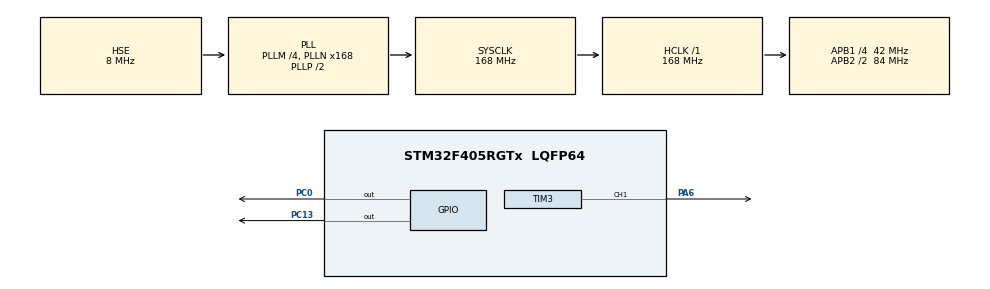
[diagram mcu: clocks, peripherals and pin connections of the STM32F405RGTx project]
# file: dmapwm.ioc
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Dma.Request0=TIM3_CH1/TRIG
Dma.TIM3_CH1/TRIG.0.Direction=DMA_MEMORY_TO_PERIPH
Dma.TIM3_CH1/TRIG.0.FIFOMode=DMA_FIFOMODE_DISABLE
Dma.TIM3_CH1/TRIG.0.Instance=DMA1_Stream4
Dma.TIM3_CH1/TRIG.0.MemDataAlignment=DMA_MDATAALIGN_HALFWORD
Dma.TIM3_CH1/TRIG.0.MemInc=DMA_MINC_ENABLE
Dma.TIM3_CH1/TRIG.0.Mode=DMA_CIRCULAR
Dma.TIM3_CH1/TRIG.0.PeriphDataAlignment=DMA_PDATAALIGN_HALFWORD
Dma.TIM3_CH1/TRIG.0.PeriphInc=DMA_PINC_DISABLE
Dma.TIM3_CH1/TRIG.0.Priority=DMA_PRIORITY_MEDIUM
Mcu.Family=STM32F4
Mcu.Name=STM32F405RGTx
Mcu.Package=LQFP64
Mcu.UserConstants=LED_PERIOD,104;LED_PRE,0
NVIC.DMA1_Stream4_IRQn=true\:0\:0\:false\:false\:true\:false\:true
NVIC.PriorityGroup=NVIC_PRIORITYGROUP_4
NVIC.TIM4_IRQn=true\:1\:0\:true\:false\:true\:true\:true
PA13.Mode=Trace_Asynchronous_SW
PA13.Signal=SYS_JTMS-SWDIO
PA14.Mode=Trace_Asynchronous_SW
PA14.Signal=SYS_JTCK-SWCLK
PA6.GPIO_PuPd=GPIO_NOPULL
PA6.GPIO_Speed=GPIO_SPEED_FREQ_VERY_HIGH
PA6.Signal=S_TIM3_CH1
PB3.Mode=Trace_Asynchronous_SW
PB3.Signal=SYS_JTDO-SWO
PC0.Signal=GPIO_Output
PC13-ANTI_TAMP.Signal=GPIO_Output
PH0-OSC_IN.Mode=HSE-External-Oscillator
PH0-OSC_IN.Signal=RCC_OSC_IN
PH1-OSC_OUT.Mode=HSE-External-Oscillator
PH1-OSC_OUT.Signal=RCC_OSC_OUT
ProjectManager.HeapSize=0x200
ProjectManager.StackSize=0x400
ProjectManager.TargetToolchain=STM32CubeIDE
RCC.48MHZClocksFreq_Value=48000000
RCC.AHBFreq_Value=168000000
RCC.APB1CLKDivider=RCC_HCLK_DIV4
RCC.APB1Freq_Value=42000000
RCC.APB1TimFreq_Value=84000000
RCC.APB2CLKDivider=RCC_HCLK_DIV2
RCC.APB2Freq_Value=84000000
RCC.APB2TimFreq_Value=168000000
RCC.CortexFreq_Value=168000000
RCC.HCLKFreq_Value=168000000
RCC.HSE_VALUE=8000000
RCC.HSI_VALUE=16000000
RCC.LSE_VALUE=32768
RCC.PLLM=4
RCC.PLLN=168
RCC.PLLQ=7
RCC.PLLSourceVirtual=RCC_PLLSOURCE_HSE
RCC.SYSCLKFreq_VALUE=168000000
RCC.SYSCLKSource=RCC_SYSCLKSOURCE_PLLCLK
RCC.VCOOutputFreq_Value=336000000
SH.S_TIM3_CH1.0=TIM3_CH1,PWM Generation1 CH1
TIM3.AutoReloadPreload=TIM_AUTORELOAD_PRELOAD_ENABLE
TIM3.Channel-PWM\ Generation1\ CH1=TIM_CHANNEL_1
TIM3.OCFastMode_PWM-PWM\ Generation1\ CH1=TIM_OCFAST_ENABLE
TIM3.Period=LED_PERIOD
TIM3.Prescaler=LED_PRE
TIM3.Pulse-PWM\ Generation1\ CH1=0
TIM3.TIM_MasterOutputTrigger=TIM_TRGO_UPDATE
TIM4.Period=4999
TIM4.Prescaler=8399
VP_TIM3_VS_ClockSourceINT.Mode=Internal
VP_TIM4_VS_ClockSourceINT.Mode=Internal
board=custom

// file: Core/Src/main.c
/* USER CODE BEGIN Header */
/**
 ******************************************************************************
 * @file           : main.c
 * @brief          : Main program body
 ******************************************************************************
 * @attention
 *
 * <h2><center>&copy; Copyright (c) 2020 Lars Thomsen &lt;lbthomsen@gmail.com&gt;
 * All rights reserved.</center></h2>
 *
 * This software component is licensed by lbthomsen under DWYDWP (Do What You
 * Damn Well Please) license.
 *
 ******************************************************************************
 */
/* USER CODE END Header */
#include "main.h"

/* USER CODE BEGIN Includes */
#include <stdio.h>
/* USER CODE END Includes */

/* USER CODE BEGIN PD */

// Buffer allocated will be twice this
#define BUFFER_SIZE 24

// LED on/off counts.  PWM timer is running 104 counts.
#define LED_PERIOD 104
#define LED_OFF 33
#define LED_ON 71
#define LED_RESET_CYCLES 10 // Found experimentally and way longer than specified in datasheet

// Define LED driver state machine states
#define LED_RES 0 // Reset state - all values should be 0 for 2 buffers
#define LED_DAT 1 // Data state - values should be taken from led_values

#define LED_ROWS 8 // The dma buffer update handles the rows and cols sequentially
#define LED_COLS 8
#define G 0
#define R 1
#define B 2

/* USER CODE END PD */

TIM_HandleTypeDef htim3;
TIM_HandleTypeDef htim4;
DMA_HandleTypeDef hdma_tim3_ch1_trig;

/* USER CODE BEGIN PV */

uint16_t dma_buffer[BUFFER_SIZE * 2] = { 0 };

uint16_t *dma_buffer_pointer;

uint8_t led_value[LED_ROWS][LED_COLS][3] = { 0 };

uint8_t led_state = LED_RES;
uint8_t res_cnt = 0;
uint8_t led_col = 0;
uint8_t led_row = 0;

uint32_t update_count = 0;

/* USER CODE END PV */

void SystemClock_Config(void);
static void MX_GPIO_Init(void);
static void MX_DMA_Init(void);
static void MX_TIM3_Init(void);
static void MX_TIM4_Init(void);

/* USER CODE BEGIN 0 */

int _write(int file, char *ptr, int len) {
	for (int i = 0; i < len; i++)
		ITM_SendChar((*ptr++));
	return len;
}

/*
 * Update next 24 bits in the dma buffer - assume dma_buffer_pointer is pointing
 * to the buffer that is safe to update.
 *
 * At the moment this one is in dire need of optimization!
 *
 */
static inline void update_buffer_next() {

	// For debugging and measuring calculation time - toggle GPIO pin
	HAL_GPIO_WritePin(GPIOC, GPIO_PIN_0, GPIO_PIN_SET);

	// A simple state machine - we're either resetting (two buffers worth of zeros) or
	// we are transmitting data

	if (led_state == LED_RES) { // Reset state - 10 or more full buffers of zeros

		for (uint8_t i = 0; i < BUFFER_SIZE; i++) { // Fill buffer with zeros
			*(uint16_t*) dma_buffer_pointer = (uint16_t) 0;
			dma_buffer_pointer++;
		}

		res_cnt++;

		if (res_cnt >= LED_RESET_CYCLES) { // done enough reset cycles
			led_col = 0;	// prepare to send data
			led_row = 0;
			led_state = LED_DAT;
		}

	} else { // LED state

		// First let's deal with the current LED
		uint8_t *led = led_value[led_col][led_row];
		for (uint8_t c = 0; c < 3; c++) { // This is the bitch - need to be optimized!
			uint8_t value = led[c];
			// Now deal with each bit
			for (uint8_t b = 0; b < 8; b++) {
				*(uint16_t*) dma_buffer_pointer =
						value >> (7 - b) != 0 ? LED_ON : LED_OFF;
				dma_buffer_pointer++;
			}
		}

		// Now move to next LED switching to reset state when all leds have been updated
		led_col++; // Next column
		if (led_col >= LED_COLS) { // reached top
			led_col = 0; // back to first
			led_row++; // and move on to next row
			if (led_row >= LED_ROWS) { // reached end
				update_count++;
				res_cnt = 0;
				led_state = LED_RES;
			}
		}

	}

	HAL_GPIO_WritePin(GPIOC, GPIO_PIN_0, GPIO_PIN_RESET);

}

// Handle built-in blue led hanging off of C13
void HAL_TIM_PeriodElapsedCallback(TIM_HandleTypeDef *htim) {
	if (htim->Instance == TIM4) {
		HAL_GPIO_TogglePin(GPIOC, GPIO_PIN_13);
	}
}

// Done sending first half of the DMA buffer - this can now safely be updated
void HAL_TIM_PWM_PulseFinishedHalfCpltCallback(TIM_HandleTypeDef *htim) {

	if (htim->Instance == TIM3) {
		dma_buffer_pointer = &dma_buffer[0];
		update_buffer_next();
	}

}

// Done sending the second half of the DMA buffer - this can now be safely updated
void HAL_TIM_PWM_PulseFinishedCallback(TIM_HandleTypeDef *htim) {

	if (htim->Instance == TIM3) {
		dma_buffer_pointer = &dma_buffer[BUFFER_SIZE];
		update_buffer_next();
	}

}

// Just throw values into led_value array - the dma interrupt will
// handle updating the dma buffer when needed
void setLedValue(uint8_t col, uint8_t row, uint8_t r, uint8_t g, uint8_t b) {

	led_value[col][row][R] = r;
	led_value[col][row][G] = g;
	led_value[col][row][B] = b;

}

/* USER CODE END 0 */

int main(void)
{

  /* MCU Configuration--------------------------------------------------------*/

  /* Reset of all peripherals, Initializes the Flash interface and the Systick. */
  HAL_Init();

  /* Configure the system clock */
  SystemClock_Config();

  /* Initialize all configured peripherals */
  MX_GPIO_Init();
  MX_DMA_Init();
  MX_TIM3_Init();
  MX_TIM4_Init();
  /* USER CODE BEGIN 2 */

	// Start the timer to get the blue led flashing every second
	HAL_TIM_Base_Start_IT(&htim4);

	// Start DMA to feed the PWM with values
	HAL_TIM_PWM_Start_DMA(&htim3, TIM_CHANNEL_1, (uint32_t*) dma_buffer,
	BUFFER_SIZE * 2);

	printf("Firing up!\n");

  /* USER CODE END 2 */

  /* Infinite loop */
  /* USER CODE BEGIN WHILE */

	uint8_t led_value_counter = 0;

	uint32_t then = 0;

	while (1) {

		uint32_t now = HAL_GetTick();
		if (now % 1000 == 0 && now != then) {

			printf("tick %5lu (update count: %5lu)\n", now, update_count);

			switch (led_value_counter) {
			case 0:
				setLedValue(0, 0, 10, 0, 0);
				break;
			case 1:
				setLedValue(0, 0, 0, 10, 0);
				break;
			case 2:
				setLedValue(0, 0, 0, 0, 10);
				break;
			case 3:
				setLedValue(0, 0, 10, 10, 0);
				break;
			case 4:
				setLedValue(0, 0, 10, 0, 10);
				break;
			case 5:
				setLedValue(0, 0, 0, 10, 10);
				break;
			case 6:
				setLedValue(0, 0, 10, 10, 10);
				break;
			}

			led_value_counter++;
			if (led_value_counter >= 7)
				led_value_counter = 0;

			then = now;
		}

    /* USER CODE END WHILE */

	}
}

void SystemClock_Config(void)
{
  RCC_OscInitTypeDef RCC_OscInitStruct = {0};
  RCC_ClkInitTypeDef RCC_ClkInitStruct = {0};

  /** Configure the main internal regulator output voltage
  */
  __HAL_RCC_PWR_CLK_ENABLE();
  __HAL_PWR_VOLTAGESCALING_CONFIG(PWR_REGULATOR_VOLTAGE_SCALE1);
  /** Initializes the RCC Oscillators according to the specified parameters
  * in the RCC_OscInitTypeDef structure.
  */
  RCC_OscInitStruct.OscillatorType = RCC_OSCILLATORTYPE_HSE;
  RCC_OscInitStruct.HSEState = RCC_HSE_ON;
  RCC_OscInitStruct.PLL.PLLState = RCC_PLL_ON;
  RCC_OscInitStruct.PLL.PLLSource = RCC_PLLSOURCE_HSE;
  RCC_OscInitStruct.PLL.PLLM = 4;
  RCC_OscInitStruct.PLL.PLLN = 168;
  RCC_OscInitStruct.PLL.PLLP = RCC_PLLP_DIV2;
  RCC_OscInitStruct.PLL.PLLQ = 7;
  if (HAL_RCC_OscConfig(&RCC_OscInitStruct) != HAL_OK)
  {
    Error_Handler();
  }
  /** Initializes the CPU, AHB and APB buses clocks
  */
  RCC_ClkInitStruct.ClockType = RCC_CLOCKTYPE_HCLK|RCC_CLOCKTYPE_SYSCLK
                              |RCC_CLOCKTYPE_PCLK1|RCC_CLOCKTYPE_PCLK2;
  RCC_ClkInitStruct.SYSCLKSource = RCC_SYSCLKSOURCE_PLLCLK;
  RCC_ClkInitStruct.AHBCLKDivider = RCC_SYSCLK_DIV1;
  RCC_ClkInitStruct.APB1CLKDivider = RCC_HCLK_DIV4;
  RCC_ClkInitStruct.APB2CLKDivider = RCC_HCLK_DIV2;

  if (HAL_RCC_ClockConfig(&RCC_ClkInitStruct, FLASH_LATENCY_5) != HAL_OK)
  {
    Error_Handler();
  }
}

static void MX_TIM3_Init(void)
{

  TIM_ClockConfigTypeDef sClockSourceConfig = {0};
  TIM_MasterConfigTypeDef sMasterConfig = {0};
  TIM_OC_InitTypeDef sConfigOC = {0};

  htim3.Instance = TIM3;
  htim3.Init.Prescaler = LED_PRE;
  htim3.Init.CounterMode = TIM_COUNTERMODE_UP;
  htim3.Init.Period = LED_PERIOD;
  htim3.Init.ClockDivision = TIM_CLOCKDIVISION_DIV1;
  htim3.Init.AutoReloadPreload = TIM_AUTORELOAD_PRELOAD_ENABLE;
  if (HAL_TIM_Base_Init(&htim3) != HAL_OK)
  {
    Error_Handler();
  }
  sClockSourceConfig.ClockSource = TIM_CLOCKSOURCE_INTERNAL;
  if (HAL_TIM_ConfigClockSource(&htim3, &sClockSourceConfig) != HAL_OK)
  {
    Error_Handler();
  }
  if (HAL_TIM_PWM_Init(&htim3) != HAL_OK)
  {
    Error_Handler();
  }
  sMasterConfig.MasterOutputTrigger = TIM_TRGO_UPDATE;
  sMasterConfig.MasterSlaveMode = TIM_MASTERSLAVEMODE_DISABLE;
  if (HAL_TIMEx_MasterConfigSynchronization(&htim3, &sMasterConfig) != HAL_OK)
  {
    Error_Handler();
  }
  sConfigOC.OCMode = TIM_OCMODE_PWM1;
  sConfigOC.Pulse = 0;
  sConfigOC.OCPolarity = TIM_OCPOLARITY_HIGH;
  sConfigOC.OCFastMode = TIM_OCFAST_ENABLE;
  if (HAL_TIM_PWM_ConfigChannel(&htim3, &sConfigOC, TIM_CHANNEL_1) != HAL_OK)
  {
    Error_Handler();
  }
  HAL_TIM_MspPostInit(&htim3);

}

static void MX_TIM4_Init(void)
{

  TIM_ClockConfigTypeDef sClockSourceConfig = {0};
  TIM_MasterConfigTypeDef sMasterConfig = {0};

  htim4.Instance = TIM4;
  htim4.Init.Prescaler = 8399;
  htim4.Init.CounterMode = TIM_COUNTERMODE_UP;
  htim4.Init.Period = 4999;
  htim4.Init.ClockDivision = TIM_CLOCKDIVISION_DIV1;
  htim4.Init.AutoReloadPreload = TIM_AUTORELOAD_PRELOAD_DISABLE;
  if (HAL_TIM_Base_Init(&htim4) != HAL_OK)
  {
    Error_Handler();
  }
  sClockSourceConfig.ClockSource = TIM_CLOCKSOURCE_INTERNAL;
  if (HAL_TIM_ConfigClockSource(&htim4, &sClockSourceConfig) != HAL_OK)
  {
    Error_Handler();
  }
  sMasterConfig.MasterOutputTrigger = TIM_TRGO_RESET;
  sMasterConfig.MasterSlaveMode = TIM_MASTERSLAVEMODE_DISABLE;
  if (HAL_TIMEx_MasterConfigSynchronization(&htim4, &sMasterConfig) != HAL_OK)
  {
    Error_Handler();
  }

}

static void MX_DMA_Init(void)
{

  /* DMA controller clock enable */
  __HAL_RCC_DMA1_CLK_ENABLE();

  /* DMA interrupt init */
  /* DMA1_Stream4_IRQn interrupt configuration */
  HAL_NVIC_SetPriority(DMA1_Stream4_IRQn, 0, 0);
  HAL_NVIC_EnableIRQ(DMA1_Stream4_IRQn);

}

static void MX_GPIO_Init(void)
{
  GPIO_InitTypeDef GPIO_InitStruct = {0};

  /* GPIO Ports Clock Enable */
  __HAL_RCC_GPIOC_CLK_ENABLE();
  __HAL_RCC_GPIOH_CLK_ENABLE();
  __HAL_RCC_GPIOA_CLK_ENABLE();
  __HAL_RCC_GPIOB_CLK_ENABLE();

  /*Configure GPIO pin Output Level */
  HAL_GPIO_WritePin(GPIOC, GPIO_PIN_13|GPIO_PIN_0, GPIO_PIN_RESET);

  /*Configure GPIO pins : PC13 PC0 */
  GPIO_InitStruct.Pin = GPIO_PIN_13|GPIO_PIN_0;
  GPIO_InitStruct.Mode = GPIO_MODE_OUTPUT_PP;
  GPIO_InitStruct.Pull = GPIO_NOPULL;
  GPIO_InitStruct.Speed = GPIO_SPEED_FREQ_LOW;
  HAL_GPIO_Init(GPIOC, &GPIO_InitStruct);

}

void Error_Handler(void)
{
}

/************************ (C) COPYRIGHT STMicroelectronics *****END OF FILE****/
